# nrf5340 register map
Vendor: Nordic Semiconductor; Series: nrf53; File version: 1
CPU: CM33 r0p2, little endian, MPU, FPU, 3 interrupt priority bits
Registers are 32-bit, read-write, reset 0x0 unless marked. A register's access mark holds for its fields unless they carry their own. Offsets are from the block's base; [hi:lo] are bit positions; lines under a group give offsets from that group; 'fields as' and 'values as' point back to an identical list.

## OSCILLATORS_NS — Oscillator control 0
Base 0x40004000
Same registers: OSCILLATORS_S 0x50004000
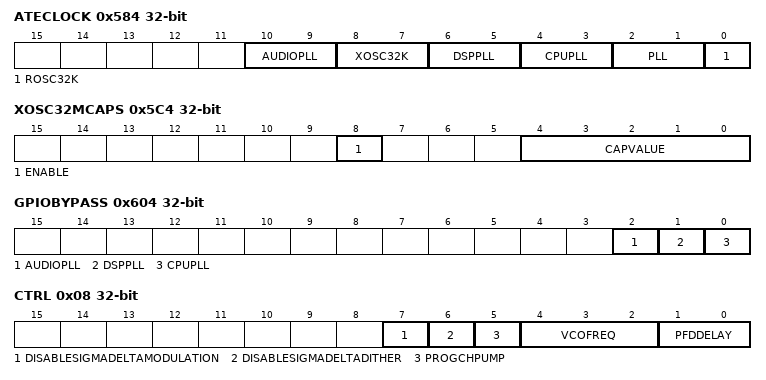
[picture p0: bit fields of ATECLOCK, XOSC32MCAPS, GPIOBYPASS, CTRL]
0x584 ATECLOCK — Analog test bus control for clock modules
  [10:9] AUDIOPLL — Configure connection of the DSP PLL to analog test bus
    0=Disconnected (ATB0 in high impedance); 1=VTUNE (Tune voltage VTUNE on ATB0); 2=OSCPLL (OSC_PLL_0V9 on ATB0); 3=OSCPLL140M (OSC_PLL_140M_1V2 on ATB0)
  [8:7] XOSC32K — Configure connection of the XOSC32K oscillator to analog test bus
  [6:5] DSPPLL — Configure connection of the DSP PLL to analog test bus
    0=Disconnected (ATB0 in high impedance); 1=VTUNE (Tune voltage VTUNE on ATB0); 2=OSCPLLVHF (OSC_PLL_VHF_0V9 on ATB0); 3=Forbidden
  [4:3] CPUPLL — Configure connection of the CPU PLL to analog test bus
    values as DSPPLL
  [2:1] PLL — Configure connection of PLL to analog test bus
    0=Disconnected; 1=VC (Connect loop filter voltage to ATB0); 2=Osc32MDiv (Connect 32 MHz divided clock to ATB1); 3=Both (Connect both VC and Osc32MDiv)
  [0] ROSC32K — Configure connection of the ROSC32K oscillator to analog test bus
0x5C4 XOSC32MCAPS — Programmable capacitance of XC1 and XC2.
  [8] ENABLE — Enable on-chip capacitors on XC1 and XC2
    0=Disabled (Capacitor disabled (use external caps)); 1=Enabled (Capacitor enabled)
  [4:0] CAPVALUE — Capacitor value = 6 + 0.57*CAPVALUE [pF] If disabled, capacitor value = 3.3 [pF]
0x600 BYPASSHFXOSC — Enable or disable bypass of HFCLK crystal oscillator with external clock source
  [0] BYPASS
    0=Disabled (Disable (use with Xtal or low-swing external source)); 1=Enabled (Enable (use with rail-to-rail external source))
0x604 GPIOBYPASS — Enable bypass from GPIO
  [2] AUDIOPLL — Enable bypass from GPIO for the AUDIO PLL
    0=Disabled (Bypass is disabled - AUDIO PLL is operating normally); 1=Enabled (Bypass is enabled - The output signal of the AUDIO PLL is replaced by the signal applied to the pad)
  [1] DSPPLL — Enable bypass from GPIO for the DSP PLL
    0=Disabled (Bypass is disabled - DSP PLL is operating normally); 1=Enabled (Bypass is enabled - The output signal of the DSP PLL is replaced by the signal applied to the pad)
  [0] CPUPLL — Enable bypass from GPIO for the CPU PLL
    0=Disabled (Bypass is disabled - CPU PLL is operating normally); 1=Enabled (Bypass is enabled - The output signal of the CPU PLL is replaced by the signal applied to the pad)
0x640 AUDIOPLL group — Unspecified
  0x00 BYPASS — AUDIO PLL bypass control
    [0] BYPASS — Enable or disable bypass of AUDIOPLL by an external clock source
      0=Disabled; 1=Enabled
  0x04 MUTE — Mute the AUDIO PLL
    [0] MUTE — Mute output clock
      0=Disabled; 1=Enabled
  0x08 CTRL — Collection of test/debug signals
    [7] DISABLESIGMADELTAMODULATION
      0=NormalOperation; 1=Disabled (Turn off Sigma-Delta Modulation, output is held constant at 0 (auPllSdmOff))
    [6] DISABLESIGMADELTADITHER
      0=NormalOperation; 1=Disabled (Turn off dither in Sigma-Delta Modulation (auPllDitherOff))
    [5] PROGCHPUMP — Program Charge Pump Current (only used for debugging)
      0=1uA (1uA (default)); 1=2uA
    [4:2] VCOFREQ — VCO frequency selection (Non-default values are only used for debugging)
      0=144MHz(default); 1=128MHz; 2=160MHz; 3=176MHz; 4=192MHz
    [1:0] PFDDELAY — Adjust internal PFD delay / CP minimum UP/DN pulse length
      0=Min (Min delay (default)); 1=50ps delay; 2=100ps delay; 3=150ps delay (max)
  0x0C VCOTRIM — VCO Trim value for the AUDIO PLL
    [5:0] VCOTRIM
  0x10 VCOTRIMOVERRIDE — Control overriding of the VCO Trim values
    [0] VCOTRIMOVEERIDE — VCO Trim value for the AUDIO PLL
      0=Disabled (VCO Trim values are coming from FICR); 1=Enabled (VCO Trim values are coming from the VCOTRIM register)
0x660 CPUPLL group — Unspecified
  0x00 BYPASS — CPU PLL bypass control
    [0] BYPASS — Enable or disable bypass of CPUPLL by an external clock source
      0=Disabled; 1=Enabled
  0x04 MUTE — Mute the CPU PLL
    [0] MUTE — Mute output clock
      0=Disabled; 1=Enabled
  0x08 CTRL — Control the behavior of the PFD
    [2] DISABLEPHASEALLIGNMENT — Adjust internal PFD delay
    [1:0] PFDDELAY — Adjust internal PFD delay / CP minimum UP/DN pulse length
      values as AUDIOPLL.CTRL.PFDDELAY
  0x0C PROGCHPUMP — Program Charge Pump Current
    [0] PROGCHPUMP — Program Charge Pump Current (only used for debugging)
      0=1uA (1uA (default)); 1=2uA
  0x10 VCOTRIM — VCO Trim value for the CPU PLL
    [5:0] VCOTRIM
  0x14 VCOTRIMOVERRIDE — Control overriding of the VCO Trim values
    [0] VCOTRIMOVEERIDE — VCO Trim value for the CPU PLL
      values as AUDIOPLL.VCOTRIMOVERRIDE.VCOTRIMOVEERIDE
0x680 PLL64M group — Unspecified
  0x00 BYPASS — PLL64M bypass control
    [0] BYPASS — Enable or disable bypass of PLL64M by an external clock source
      0=Disabled; 1=Enabled
  0x04 MUTE — Mute the PLL64M
    [0] MUTE — Mute output clock
      0=Disabled; 1=Enabled
  0x08 PROGCHPUMP — Program Charge Pump Current
    [0] PROGCHPUMP — Program Charge Pump Current (only used for debugging)
0x6A0 DSPPLL group — Unspecified
  0x00 BYPASS — DSP PLL bypass control
    [0] BYPASS — Enable or disable bypass of DSPPLL by an external clock source
      0=Disabled; 1=Enabled
  0x04 MUTE — Mute the DSP PLL
    [0] MUTE — Mute output clock
      0=Disabled; 1=Enabled
  0x08 FREQ reset 0x4 — Frequency selection
    [2:0] FREQ — Frequency selection for the DSP PLL
      0=128MHz; 1=144MHz; 2=160MHz; 3=176MHz; 4=192 MHz (default)
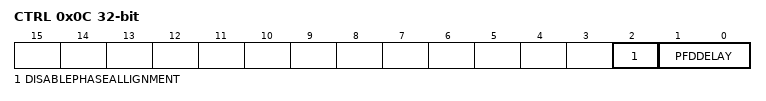
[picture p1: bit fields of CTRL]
  0x0C CTRL — Control the behavior of the PFD
    fields as CPUPLL.CTRL
  0x10 PROGCHPUMP — Program Charge Pump Current
    fields as CPUPLL.PROGCHPUMP
  0x14 VCOTRIM — VCO Trim value for the DSP PLL
    [5:0] VCOTRIM
  0x18 VCOTRIMOVERRIDE — Control overriding of the VCO Trim values
    [0] VCOTRIMOVEERIDE — VCO Trim value for the DSP PLL
      values as AUDIOPLL.VCOTRIMOVERRIDE.VCOTRIMOVEERIDE
0x6C0 XOSC32KI group — Unspecified
  0x00 BYPASS32KI — Enable or disable bypass of LFCLK crystal oscillator with external clock source
    fields as BYPASSHFXOSC
  0x04 POWERDOWN32KI — Power up or power down of LFCLK crystal oscillator
    [0] POWERDOWN32KI — Power up or power down LFCLK crystal oscillator
      0=Power up LFCLK crystal oscillator; 1=Power down LFCLK crystal oscillator
  0x08 EXTBIAS — Control the use of a external bias current
    [0] EXTBIAS
      0=Disabled (Internal bias current is used); 1=Enabled (External bias current is used)
  0x0C MUTE — Disable clock output
    [0] MUTE
      0=NotMuted (Clock is outputted on OSC_32K_0V9); 1=Muted (Clock is muted. OSC_32K_0V9 is zero)
  0x10 INTCAP — Control usage of internal load capacitors
    [1:0] INTCAP
      0=External (Use external load capacitors); 1=C6PF (6pF internal load capacitance); 2=C7PF (7pF internal load capacitance); 3=C11PF (11pf internal load capacitance)
  0x14 CAPTRIM — On-chip capacitance trimming
    [2:0] CAPTRIM
      0=TRIM0 (0 percent); 1=TRIM12P5 (+12.5 percent); 2=TRIM25 (+25 percent); 6=TRIMM25 (-25 percent); 7=TRIMM12P5 (-12.5 percent)
  0x18 CONSTCURR — Control Pierce inverter bias current
    [0] CONSTCURR — Select bias current control
      0=Regulated (Bias current is controlled by the amplitude regulator); 1=Constant (Bias current is constant)
  0x1C CONSTCURRTRIM — Control current bias when CONSTCURR == 1
    [3:0] CONSTCURRTRIM
  0x20 AREGHIGHCURR — Increase current in amplitude regulator
    [0] AREGHIGHCURR
